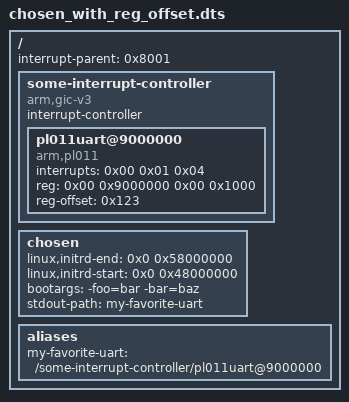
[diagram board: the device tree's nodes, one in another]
// Copyright 2023 The Fuchsia Authors. All rights reserved.
// Use of this source code is governed by a BSD-style license that can be
// found in the LICENSE file.

/dts-v1/;

/ {
  interrupt-parent = <0x8001>;
  #size-cells = <0x02>;
  #address-cells = <0x02>;
    some-interrupt-controller {
        #address-cells = <0x02>;
        #size-cells = <0x02>;
        #interrupt-cells = <0x03>;
        compatible = "arm,gic-v3";
        phandle = <0x8001>;
        interrupt-controller;
        pl011uart@9000000 {
          interrupts = <0x00 0x01 0x04>;
          reg = <0x00 0x9000000 0x00 0x1000>;
          reg-offset = <0x123>;
          compatible = "arm,pl011\0arm,primecell";
        };
    };

    chosen {
    linux,initrd-end = <0x0 0x58000000>;
    linux,initrd-start = <0x0 0x48000000>;
    bootargs = "-foo=bar -bar=baz";
    stdout-path = "my-favorite-uart";
    };

    aliases {
        my-favorite-uart = "/some-interrupt-controller/pl011uart@9000000";
    };
};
